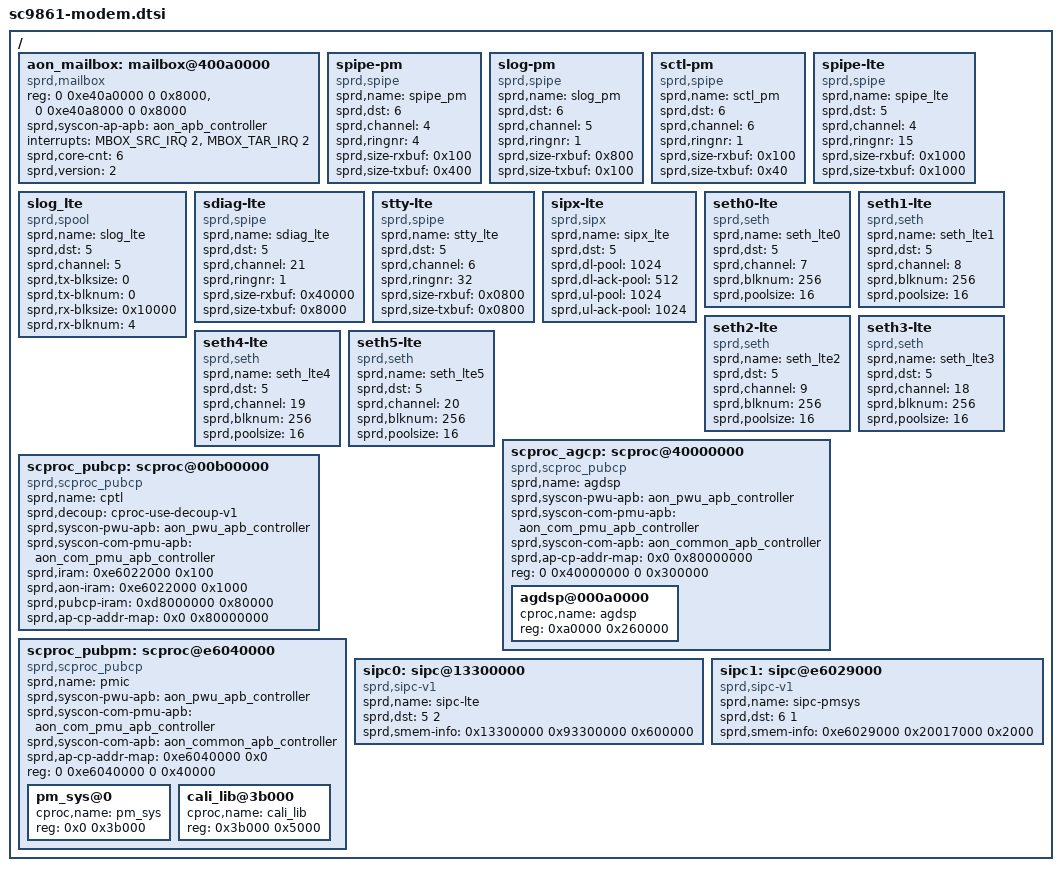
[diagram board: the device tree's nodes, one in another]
/*
 * Spreadtrum SC9830 staging board DTSI file
 * These dt code has not been reviewed and temporarily used for
 * working.
 *
 * Copyright (C) 2015, Spreadtrum Communications Inc.
 *
 * This file is licensed under a dual GPLv2 or X11 license.
 */

/ {
	aon_mailbox: mailbox@400a0000 {
		compatible = "sprd,mailbox";
		reg = <0 0xe40a0000 0 0x8000>,
		      <0 0xe40a8000 0 0x8000>;
		sprd,syscon-ap-apb = <&aon_apb_controller>;
		interrupts = <MBOX_SRC_IRQ 2>,
			     <MBOX_TAR_IRQ 2>;
		sprd,core-cnt = <6>;
		sprd,version = <2>;
	};

	spipe-pm {
		compatible = "sprd,spipe";
		sprd,name = "spipe_pm";
		sprd,dst = <6>;
		sprd,channel = <4>;
		sprd,ringnr = <4>;
		sprd,size-rxbuf = <0x100>; /* 256 */
		sprd,size-txbuf = <0x400>; /* 1024 */
	};

	slog-pm {
		compatible = "sprd,spipe";
		sprd,name = "slog_pm";
		sprd,dst = <6>;
		sprd,channel = <5>;
		sprd,ringnr = <1>;
		sprd,size-rxbuf = <0x800>; /* 2*1024*/
		sprd,size-txbuf = <0x100>; /* 256 */
	};

	sctl-pm {
		compatible = "sprd,spipe";
		sprd,name = "sctl_pm";
		sprd,dst = <6>;
		sprd,channel = <6>;
		sprd,ringnr = <1>;
		sprd,size-rxbuf = <0x100>; /* 128*/
		sprd,size-txbuf = <0x40>; /* 64 */
	};

	spipe-lte {
		compatible = "sprd,spipe";
		sprd,name = "spipe_lte";
		sprd,dst = <5>;
		sprd,channel = <4>;
		sprd,ringnr = <15>;
		sprd,size-rxbuf = <0x1000>; /* 4*1024 */
		sprd,size-txbuf = <0x1000>; /* 4*1024 */
	};

	slog_lte {
		compatible = "sprd,spool";
		sprd,name = "slog_lte";
		sprd,dst = <5>;
		sprd,channel = <5>;
		sprd,tx-blksize = <0>;
		sprd,tx-blknum = <0>;
		sprd,rx-blksize = <0x10000>; /* 64k*/
		sprd,rx-blknum = <4>;
	};

	sdiag-lte {
		compatible = "sprd,spipe";
		sprd,name = "sdiag_lte";
		sprd,dst = <5>;
		sprd,channel = <21>;
		sprd,ringnr = <1>;
		sprd,size-rxbuf = <0x40000>; /* 256*1024*/
		sprd,size-txbuf = <0x8000>; /* 32*1024 */
	};

	stty-lte {
		compatible = "sprd,spipe";
		sprd,name = "stty_lte";
		sprd,dst = <5>;
		sprd,channel = <6>;
		sprd,ringnr = <32>;
		sprd,size-rxbuf = <0x0800>; /* 2*1024*/
		sprd,size-txbuf = <0x0800>; /* 2*1024 */
	};

	sipx-lte {
		compatible = "sprd,sipx";
		sprd,name = "sipx_lte";
		sprd,dst = <5>;
		sprd,dl-pool = <1024>;
		sprd,dl-ack-pool = <512>;
		sprd,ul-pool = <1024>;
		sprd,ul-ack-pool = <1024>;
	};

	seth0-lte {
		compatible = "sprd,seth";
		sprd,name = "seth_lte0";
		sprd,dst = <5>;
		sprd,channel = <7>;
		sprd,blknum = <256>;
		sprd,poolsize = <16>;
		};

	seth1-lte {
		compatible = "sprd,seth";
		sprd,name = "seth_lte1";
		sprd,dst = <5>;
		sprd,channel = <8>;
		sprd,blknum = <256>;
		sprd,poolsize = <16>;
		};

	seth2-lte {
		compatible = "sprd,seth";
		sprd,name = "seth_lte2";
		sprd,dst = <5>;
		sprd,channel = <9>;
		sprd,blknum = <256>;
		sprd,poolsize = <16>;
		};

	seth3-lte {
		compatible = "sprd,seth";
		sprd,name = "seth_lte3";
		sprd,dst = <5>;
		sprd,channel = <18>;
		sprd,blknum = <256>;
		sprd,poolsize = <16>;
		};

	seth4-lte {
		compatible = "sprd,seth";
		sprd,name = "seth_lte4";
		sprd,dst = <5>;
		sprd,channel = <19>;
		sprd,blknum = <256>;
		sprd,poolsize = <16>;
		};

	seth5-lte {
		compatible = "sprd,seth";
		sprd,name = "seth_lte5";
		sprd,dst = <5>;
		sprd,channel = <20>;
		sprd,blknum = <256>;
		sprd,poolsize = <16>;
		};

	scproc_agcp: scproc@40000000 {
		compatible = "sprd,scproc_pubcp";
		sprd,name = "agdsp";
		sprd,syscon-pwu-apb = <&aon_pwu_apb_controller>;
		sprd,syscon-com-pmu-apb = <&aon_com_pmu_apb_controller>;
		sprd,syscon-com-apb = <&aon_common_apb_controller>;
		sprd,ap-cp-addr-map = <0x0 0x80000000>;
		reg = <0 0x40000000 0 0x300000>;/* <agdsp_start total_size> */
		#address-cells = <1>;
		#size-cells = <1>;
		/* segnr=1 */
		ranges = <0x000a0000 0 0x400a0000 0x260000>;
		agdsp@000a0000 {
			cproc,name = "agdsp";
			reg = <0xa0000 0x260000>; /* <agdsp_addr size> */
		};
	};

	scproc_pubcp: scproc@00b00000 {
		compatible = "sprd,scproc_pubcp";
		sprd,name = "cptl";
		sprd,decoup = "cproc-use-decoup-v1";
		sprd,syscon-pwu-apb = <&aon_pwu_apb_controller>;
		sprd,syscon-com-pmu-apb = <&aon_com_pmu_apb_controller>;
		sprd,iram = <0xe6022000 0x100>;
		sprd,aon-iram = <0xe6022000 0x1000>;
		sprd,pubcp-iram = <0xd8000000 0x80000>;
		sprd,ap-cp-addr-map = <0x0 0x80000000>; /* ap: 0x0 <=> cp: 0x80000000 */
	};

	scproc_pubpm: scproc@e6040000 {
		compatible = "sprd,scproc_pubcp";
		sprd,name = "pmic";
		sprd,syscon-pwu-apb = <&aon_pwu_apb_controller>;
		sprd,syscon-com-pmu-apb = <&aon_com_pmu_apb_controller>;
		sprd,syscon-com-apb = <&aon_common_apb_controller>;
		sprd,ap-cp-addr-map = <0xe6040000 0x0>;
		reg = <0 0xe6040000 0 0x40000>; /* <sp_start_addr total_size> */
		#address-cells = <1>;
		#size-cells = <1>;
		/* segnr=1 */
		ranges = <0x0 0x0 0xe6040000 0x3b000>,
			 <0x3b000 0x0 0xe607b000 0x5000>;
		pm_sys@0 {
			cproc,name = "pm_sys";
			reg = <0x0 0x3b000>; /* <pmsys_addr size> */
		};
		cali_lib@3b000 {
			cproc,name = "cali_lib";
			reg = <0x3b000 0x5000>; /* <cali_lib_addr size> */
		};
	};

	sipc0: sipc@13300000 {
		compatible = "sprd,sipc-v1";
		sprd,name = "sipc-lte";
		sprd,dst = <5 2>; /* <dst core-id> */
		/* <ap-addr dst-maped-addr size> */
		sprd,smem-info = <0x13300000 0x93300000 0x600000>;
	};

	sipc1: sipc@e6029000 {
		compatible = "sprd,sipc-v1";
		sprd,name = "sipc-pmsys";
		sprd,dst = <6 1>; /* <dst core-id> */
		/* <ap-addr dst-maped-addr size> */
		sprd,smem-info = <0xe6029000 0x20017000 0x2000>;
	};
};

